# AE350_4GB register map
Vendor: Andes Technology; Series: AE350; File version: 1.3.0
Registers are 32-bit, read-write, reset 0x0 unless marked. A register's access mark holds for its fields unless they carry their own. Offsets are from the block's base; [hi:lo] are bit positions; {n}, {i} and the like mark numbered series; 'fields as' and 'values as' point back to an identical list.

## PLIC_Target8_11 — Platform-Level Interrupt Controller
Base 0xE4000000
{0x200000+0x1000*i} Target{i}PriorityThreshold (i=8..11)
  [?] FIELD_1
{0x200004+0x1000*i} Target{i}ClaimComplete (i=8..11) — Target {i} Claim and Complete
  [9:0] INTERRUPT_ID — Interrupt source ID
{0x208400+4i} Target8PreemptedPriorityStack_{i} (i=0..7) — Target 8 preempted priority stack
  [?] FIELD_1
{0x209400+4i} Target9PreemptedPriorityStack_{i} (i=0..7) — Target 9 preempted priority stack
  [?] FIELD_1
{0x20A400+4i} Target10PreemptedPriorityStack_{i} (i=0..7) — Target 10 preempted priority stack
  [?] FIELD_1
{0x20B400+4i} Target11PreemptedPriorityStack_{i} (i=0..7) — Target 11 preempted priority stack
  [?] FIELD_1

## PLIC_Target12_15 — Platform-Level Interrupt Controller
Base 0xE4000000
{0x200000+0x1000*i} Target{i}PriorityThreshold (i=12..15)
  [?] FIELD_1
{0x200004+0x1000*i} Target{i}ClaimComplete (i=12..15) — Target {i} Claim and Complete
  [9:0] INTERRUPT_ID — Interrupt source ID
{0x20C400+4i} Target12PreemptedPriorityStack_{i} (i=0..7) — Target 12 preempted priority stack
  [?] FIELD_1
{0x20D400+4i} Target13PreemptedPriorityStack_{i} (i=0..7) — Target 13 preempted priority stack
  [?] FIELD_1
{0x20E400+4i} Target14PreemptedPriorityStack_{i} (i=0..7) — Target 14 preempted priority stack
  [?] FIELD_1
{0x20F400+4i} Target15PreemptedPriorityStack_{i} (i=0..7) — Target 15 preempted priority stack
  [?] FIELD_1

## PLMT — Platform-Level Machine Timer
Base 0xE6000000
0x00 mtime_32 — Machine Time Register [31:0]
  [?] FIELD_1
0x04 mtime_64 — Machine Time Register [63:32]
  [?] FIELD_1
{0x8+8i} mtimecmp{i}_32 reset 0xFFFFFFFF (i=0..3) — Machine Time Compare Register {i} [31:0]
  [?] FIELD_1
{0xC+8i} mtimecmp{i}_64 reset 0xFFFFFFFF (i=0..3) — Machine Time Compare Register {i} [63:32]
  [?] FIELD_1

## PLDM — Platform-Level Debug Module
Base 0xE6800000
{0x0+4i} debug_rom{i} ro (i=0..22)
  [?] FIELD_1 rw
{0x80+4i} progbuf{i} (i=0..15) — Program Buffer {i}
  [?] FIELD_1
{0xC0+4i} data{i} (i=0..11) — Abstract Data {i}
  [?] FIELD_1
{0x100+4i} absprog{i} ro (i=0..4) — Abstract Program {i}
  [?] FIELD_1 rw
0x120 command
  [?] FIELD_1
0x124 notify
  [?] FIELD_1
0x128 resume
  [?] FIELD_1
0x12C exception
  [?] FIELD_1
0x138 serial — Serial Port
  [?] FIELD_1
{0x140+4i} halt{i}_region (i=0..7) — Halt Region {i}
  [?] FIELD_1
0x160 clr_absbusy — Clear Absbusy
  [?] FIELD_1

## APB_Bridge — APB Bridge Registers
Base 0xF0000000
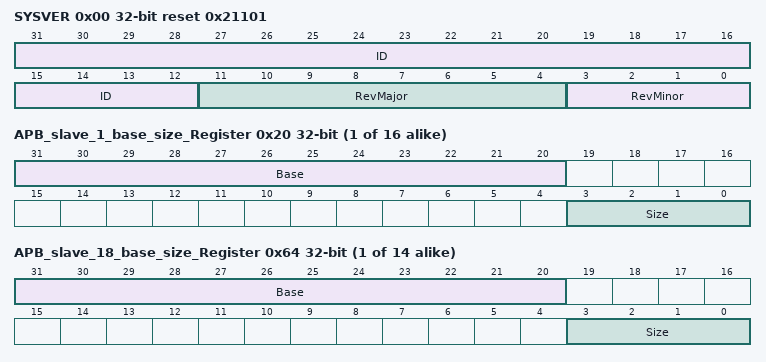
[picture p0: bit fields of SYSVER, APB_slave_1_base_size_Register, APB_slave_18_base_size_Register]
0x00 SYSVER ro reset 0x21101 — ID and Revision Register
  [31:12] ID — ID number for ATCAPBBRG100
  [11:4] RevMajor — Major revision number
  [3:0] RevMinor — Minor revision number
0x14 Control
  [0] WBUF_EN — Force the write buffering for all writes
{0x1C+4i} APB_slave_{i}_base_size_Register (i=1..16)
  [31:20] Base ro — Base address
  [3:0] Size ro — Size of the address space
0x60 APB_slave_17_base_size_Register
  [31:20] Base ro — Base address
  [31:20] Base_2 ro — Base address
  [3:0] Size ro — Size of the address space
  [3:0] Size_2 ro — Size of the address space
{0x1C+4i} APB_slave_{i}_base_size_Register (i=18..31)
  fields as APB_slave_1_base_size_Register

## SMU — System Management Unit Registers
Base 0xF0100000
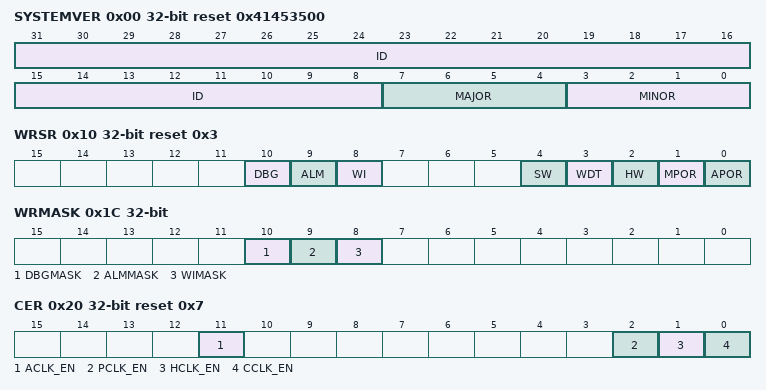
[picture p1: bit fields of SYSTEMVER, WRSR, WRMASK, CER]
0x00 SYSTEMVER ro reset 0x41453500 — SYSTEM ID & Revision Register.
  [31:8] ID
  [7:4] MAJOR — Major revision number
  [3:0] MINOR — Minor revision number
0x04 BOARDID ro reset 0x174B010
  [31:0] ID — Board ID
0x08 SYSTEMCFG ro reset 0x1 — SYSTEM Configuration Register
  [7:0] CORENUM — CPU core number
0x10 WRSR reset 0x3 — Wakeup and reset status register.
  [10] DBG — Wake-up by debug requests
  [9] ALM — Wake-up by RTC alarm events
  [8] WI — Wake-up by external events
  [4] SW — Software Reset
  [3] WDT — Watchdog Reset
  [2] HW — Hardware Reset
  [1] MPOR — MPD Power-On Reset
  [0] APOR — AOPD Power-On Reset
0x14 SMUCR — SMU command register.
  [7:0] SMUCMD — SMU command
0x1C WRMASK — Wakeup and reset mask register.
  [10] DBGMASK — Indicates whether debug requests will trigger wake-ups
  [9] ALMMASK — Indicates whether RTC events will trigger wake-ups
  [8] WIMASK — Indicates whether external events will trigger wake-ups
0x20 CER reset 0x7 — Clock enable register.
  [11] ACLK_EN — AXI bus clock enable
  [2] PCLK_EN — Main APB bus clock enable
  [1] HCLK_EN — AHB bus clock enable
  [0] CCLK_EN — Processor clock enable
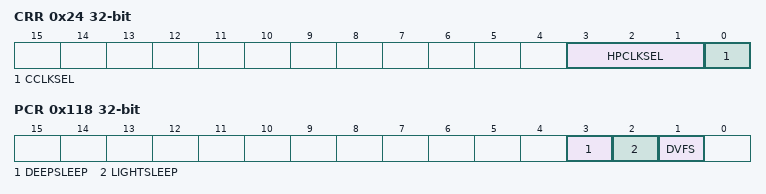
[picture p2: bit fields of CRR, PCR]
0x24 CRR — Clock ratio register.
  [3:1] HPCLKSEL — HCLK and PCLK clock ratio select
  [0] CCLKSEL — Processor clock select
0x30 URREG0 — User Defined Register 0
  [?] FIELD_1
0x34 URREG1 — User Defined Register 1
  [?] FIELD_1
0x40 SCRATCH — Scratch Pad Register
  [?] FIELD_1
0x44 HART_RESET_CTL — Hart Reset Control Register
  [0] HART0_RESET ro — Hardwired to 1
{0x50+4i} HART{i}_RESET_VECTOR (i=0..3)
  [?] FIELD_1
0x100 PWCR — Power Mode Cycle Register
  [?] FIELD_1
0x104 PWDIR — Power Mode Disable Initialization Register
  [?] FIELD_1
0x108 PDSR — Power Domain Select Register
  [?] FIELD_1
0x10C PSR — Power Status Register
  [?] FIELD_1
0x110 PWRR — Power Wakeup Record Register
  [?] FIELD_1
0x114 PWER — Power Wakeup Enable Register
  [?] FIELD_1
0x118 PCR — Power Control Register
  [3] DEEPSLEEP, [2] LIGHTSLEEP, [1] DVFS
0x11C PIR — Power Interrupt Register
  [1] PIR_EN — Enable PIR
